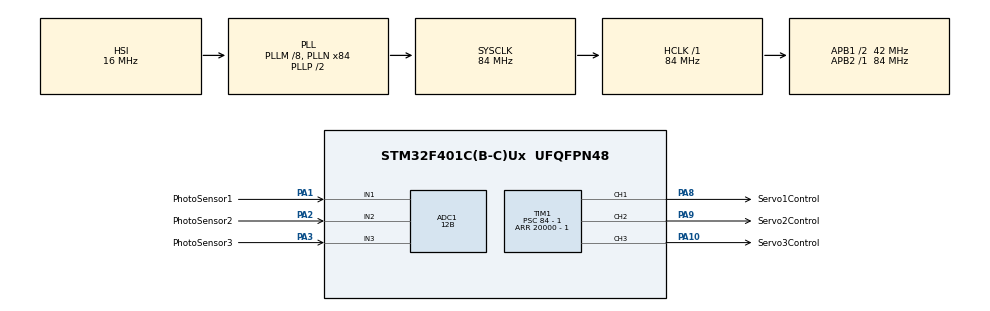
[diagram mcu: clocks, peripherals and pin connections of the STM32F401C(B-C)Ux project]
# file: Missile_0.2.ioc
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ADC1.Channel-0\#ChannelRegularConversion=ADC_CHANNEL_1
ADC1.Channel-1\#ChannelRegularConversion=ADC_CHANNEL_2
ADC1.Channel-2\#ChannelRegularConversion=ADC_CHANNEL_3
ADC1.Channel-3\#ChannelInjectedConversion=ADC_CHANNEL_1
ADC1.Channel-4\#ChannelInjectedConversion=ADC_CHANNEL_2
ADC1.Channel-5\#ChannelInjectedConversion=ADC_CHANNEL_3
ADC1.ContinuousConvMode=ENABLE
ADC1.DMAContinuousRequests=ENABLE
ADC1.ExternalTrigInjecConv=ADC_EXTERNALTRIGINJECCONV_T4_TRGO
ADC1.InjNumberOfConversion=3
ADC1.InjectedOffset-3\#ChannelInjectedConversion=0
ADC1.InjectedOffset-4\#ChannelInjectedConversion=0
ADC1.InjectedOffset-5\#ChannelInjectedConversion=0
ADC1.InjectedRank-3\#ChannelInjectedConversion=1
ADC1.InjectedRank-4\#ChannelInjectedConversion=2
ADC1.InjectedRank-5\#ChannelInjectedConversion=3
ADC1.NbrOfConversion=3
ADC1.NbrOfConversionFlag=1
ADC1.Rank-0\#ChannelRegularConversion=1
ADC1.Rank-1\#ChannelRegularConversion=2
ADC1.Rank-2\#ChannelRegularConversion=3
ADC1.Resolution=ADC_RESOLUTION_12B
ADC1.SamplingTime-0\#ChannelRegularConversion=ADC_SAMPLETIME_144CYCLES
ADC1.SamplingTime-1\#ChannelRegularConversion=ADC_SAMPLETIME_144CYCLES
ADC1.SamplingTime-2\#ChannelRegularConversion=ADC_SAMPLETIME_144CYCLES
ADC1.SamplingTime-3\#ChannelInjectedConversion=ADC_SAMPLETIME_3CYCLES
ADC1.SamplingTime-4\#ChannelInjectedConversion=ADC_SAMPLETIME_3CYCLES
ADC1.SamplingTime-5\#ChannelInjectedConversion=ADC_SAMPLETIME_3CYCLES
ADC1.ScanConvMode=ENABLE
ADC1.master=1
Dma.ADC1.0.Direction=DMA_PERIPH_TO_MEMORY
Dma.ADC1.0.FIFOMode=DMA_FIFOMODE_DISABLE
Dma.ADC1.0.Instance=DMA2_Stream0
Dma.ADC1.0.MemDataAlignment=DMA_MDATAALIGN_WORD
Dma.ADC1.0.MemInc=DMA_MINC_ENABLE
Dma.ADC1.0.Mode=DMA_CIRCULAR
Dma.ADC1.0.PeriphDataAlignment=DMA_PDATAALIGN_WORD
Dma.ADC1.0.PeriphInc=DMA_PINC_DISABLE
Dma.ADC1.0.Priority=DMA_PRIORITY_LOW
Dma.Request0=ADC1
Mcu.Family=STM32F4
Mcu.Name=STM32F401C(B-C)Ux
Mcu.Package=UFQFPN48
NVIC.DMA2_Stream0_IRQn=true\:0\:0\:false\:false\:true\:false\:true\:true
NVIC.PriorityGroup=NVIC_PRIORITYGROUP_4
PA1.GPIO_Label=PhotoSensor1
PA1.Signal=ADCx_IN1
PA10.GPIO_Label=Servo3Control
PA10.Signal=S_TIM1_CH3
PA13.Mode=Serial_Wire
PA13.Signal=SYS_JTMS-SWDIO
PA14.Mode=Serial_Wire
PA14.Signal=SYS_JTCK-SWCLK
PA2.GPIO_Label=PhotoSensor2
PA2.Signal=ADCx_IN2
PA3.GPIO_Label=PhotoSensor3
PA3.Signal=ADCx_IN3
PA8.GPIO_Label=Servo1Control
PA8.Signal=S_TIM1_CH1
PA9.GPIO_Label=Servo2Control
PA9.Signal=S_TIM1_CH2
PH0\ -\ OSC_IN.Mode=HSE-External-Oscillator
PH0\ -\ OSC_IN.Signal=RCC_OSC_IN
PH1\ -\ OSC_OUT.Mode=HSE-External-Oscillator
PH1\ -\ OSC_OUT.Signal=RCC_OSC_OUT
ProjectManager.HeapSize=0x200
ProjectManager.StackSize=0x400
ProjectManager.TargetToolchain=Makefile
RCC.48MHZClocksFreq_Value=42000000
RCC.AHBFreq_Value=84000000
RCC.APB1CLKDivider=RCC_HCLK_DIV2
RCC.APB1Freq_Value=42000000
RCC.APB1TimFreq_Value=84000000
RCC.APB2Freq_Value=84000000
RCC.APB2TimFreq_Value=84000000
RCC.CortexFreq_Value=84000000
RCC.HCLKFreq_Value=84000000
RCC.HSE_VALUE=25000000
RCC.HSI_VALUE=16000000
RCC.LSE_VALUE=32768
RCC.PLLM=8
RCC.PLLN=84
RCC.SYSCLKFreq_VALUE=84000000
RCC.SYSCLKSource=RCC_SYSCLKSOURCE_PLLCLK
RCC.VCOOutputFreq_Value=168000000
SH.ADCx_IN1.0=ADC1_IN1,IN1
SH.ADCx_IN2.0=ADC1_IN2,IN2
SH.ADCx_IN3.0=ADC1_IN3,IN3
SH.S_TIM1_CH1.0=TIM1_CH1,PWM Generation1 CH1
SH.S_TIM1_CH2.0=TIM1_CH2,PWM Generation2 CH2
SH.S_TIM1_CH3.0=TIM1_CH3,PWM Generation3 CH3
STMicroelectronics.X-CUBE-ALGOBUILD.1.3.0.LibraryCcDSPOoLibraryJjDSPOoLibrary=true
TIM1.Channel-PWM\ Generation1\ CH1=TIM_CHANNEL_1
TIM1.Channel-PWM\ Generation2\ CH2=TIM_CHANNEL_2
TIM1.Channel-PWM\ Generation3\ CH3=TIM_CHANNEL_3
TIM1.Period=20000 - 1
TIM1.Prescaler=84 - 1
TIM4.Period=100
TIM4.Prescaler=21
TIM4.TIM_MasterOutputTrigger=TIM_TRGO_UPDATE
VP_STMicroelectronics.X-CUBE-ALGOBUILD_VS_DSPOoLibraryJjLibrary_1.3.0_1.3.0.Mode=DSPOoLibraryJjLibrary
VP_TIM1_VS_ClockSourceINT.Mode=Internal
VP_TIM4_VS_ClockSourceINT.Mode=Internal
board=custom

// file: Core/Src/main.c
/* USER CODE BEGIN Header */
/**
  ******************************************************************************
  * @file           : main.c
  * @brief          : Main program body
  ******************************************************************************
  * @attention
  *
  * Copyright (c) 2022 STMicroelectronics.
  * All rights reserved.
  *
  * This software is licensed under terms that can be found in the LICENSE file
  * in the root directory of this software component.
  * If no LICENSE file comes with this software, it is provided AS-IS.
  *
  ******************************************************************************
  */
/* USER CODE END Header */
#include "main.h"
#include "adc.h"
#include "dma.h"
#include "tim.h"
#include "gpio.h"

/* USER CODE BEGIN Includes */

#include "PhotoSensor.h"
#include "AdcDataHandle.h"
#include "ServoControl.h"
/* USER CODE END Includes */

void SystemClock_Config(void);

/* USER CODE BEGIN 0 */
static void PrivateHardWareOpen(void);

/* USER CODE END 0 */

int main(void)
{

  /* MCU Configuration--------------------------------------------------------*/

  /* Reset of all peripherals, Initializes the Flash interface and the Systick. */
  HAL_Init();

  /* Configure the system clock */
  SystemClock_Config();

  /* Initialize all configured peripherals */
  MX_GPIO_Init();
  MX_DMA_Init();
  MX_ADC1_Init();
  MX_TIM4_Init();
  MX_TIM1_Init();
  /* USER CODE BEGIN 2 */
	PrivateHardWareOpen();
  /* USER CODE END 2 */

  /* Infinite loop */
  while (1)
  {

  }
}

void SystemClock_Config(void)
{
  RCC_OscInitTypeDef RCC_OscInitStruct = {0};
  RCC_ClkInitTypeDef RCC_ClkInitStruct = {0};

  /** Configure the main internal regulator output voltage
  */
  __HAL_RCC_PWR_CLK_ENABLE();
  __HAL_PWR_VOLTAGESCALING_CONFIG(PWR_REGULATOR_VOLTAGE_SCALE2);

  /** Initializes the RCC Oscillators according to the specified parameters
  * in the RCC_OscInitTypeDef structure.
  */
  RCC_OscInitStruct.OscillatorType = RCC_OSCILLATORTYPE_HSI;
  RCC_OscInitStruct.HSIState = RCC_HSI_ON;
  RCC_OscInitStruct.HSICalibrationValue = RCC_HSICALIBRATION_DEFAULT;
  RCC_OscInitStruct.PLL.PLLState = RCC_PLL_ON;
  RCC_OscInitStruct.PLL.PLLSource = RCC_PLLSOURCE_HSI;
  RCC_OscInitStruct.PLL.PLLM = 8;
  RCC_OscInitStruct.PLL.PLLN = 84;
  RCC_OscInitStruct.PLL.PLLP = RCC_PLLP_DIV2;
  RCC_OscInitStruct.PLL.PLLQ = 4;
  if (HAL_RCC_OscConfig(&RCC_OscInitStruct) != HAL_OK)
  {
    Error_Handler();
  }

  /** Initializes the CPU, AHB and APB buses clocks
  */
  RCC_ClkInitStruct.ClockType = RCC_CLOCKTYPE_HCLK|RCC_CLOCKTYPE_SYSCLK
                              |RCC_CLOCKTYPE_PCLK1|RCC_CLOCKTYPE_PCLK2;
  RCC_ClkInitStruct.SYSCLKSource = RCC_SYSCLKSOURCE_PLLCLK;
  RCC_ClkInitStruct.AHBCLKDivider = RCC_SYSCLK_DIV1;
  RCC_ClkInitStruct.APB1CLKDivider = RCC_HCLK_DIV2;
  RCC_ClkInitStruct.APB2CLKDivider = RCC_HCLK_DIV1;

  if (HAL_RCC_ClockConfig(&RCC_ClkInitStruct, FLASH_LATENCY_2) != HAL_OK)
  {
    Error_Handler();
  }
}

/* USER CODE BEGIN 4 */
//外部设备初始化函数，用于初始化飞镖弹体特殊外�????
static void PrivateHardWareOpen(void)
{
  //光传感器初始化
  PhotoSensorAdcOpen();
  //舵机初始化
  ServoControlInit();

}
/* USER CODE END 4 */

void Error_Handler(void)
{
  __disable_irq();
  while (1)
  {
  }
}
